# AT91SAM9M11 register map
Vendor: Atmel; File version: 20130207
CPU: 
Registers are 32-bit, read-write, no defined reset value unless marked. A register's access mark holds for its fields unless they carry their own. Offsets are from the block's base; [hi:lo] are bit positions; {n}, {i} and the like mark numbered series; 'fields as' and 'values as' point back to an identical list.

## PMC — Power Management Controller
Base 0xFFFFFC00
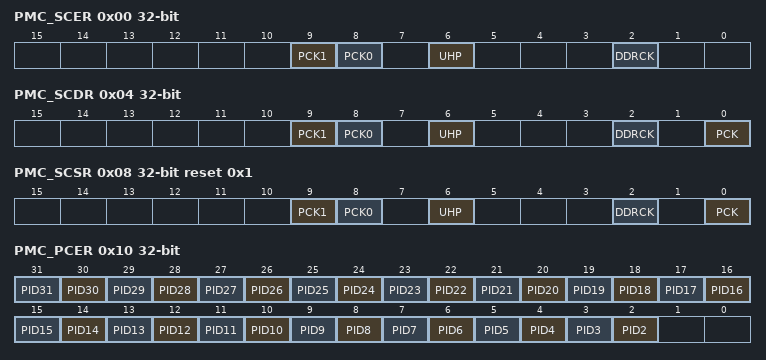
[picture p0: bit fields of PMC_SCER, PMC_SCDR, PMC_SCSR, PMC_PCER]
0x00 PMC_SCER wo — System Clock Enable Register
  [9] PCK1 — Programmable Clock 1 Output Enable
  [8] PCK0 — Programmable Clock 0 Output Enable
  [6] UHP — USB Host OHCI Clocks Enable
  [2] DDRCK — DDR Clock Enable
0x04 PMC_SCDR wo — System Clock Disable Register
  [9] PCK1 — Programmable Clock 1 Output Disable
  [8] PCK0 — Programmable Clock 0 Output Disable
  [6] UHP — USB Host OHCI Clock Disable
  [2] DDRCK — DDR Clock Disable
  [0] PCK — Processor Clock Disable
0x08 PMC_SCSR ro reset 0x1 — System Clock Status Register
  [9] PCK1 — Programmable Clock 1 Output Status
  [8] PCK0 — Programmable Clock 0 Output Status
  [6] UHP — USB Host Port Clock Status
  [2] DDRCK — DDR Clock Status
  [0] PCK — Processor Clock Status
0x10 PMC_PCER wo — Peripheral Clock Enable Register
  [n] PID{n} (n=2..31) — Peripheral Clock {n} Enable
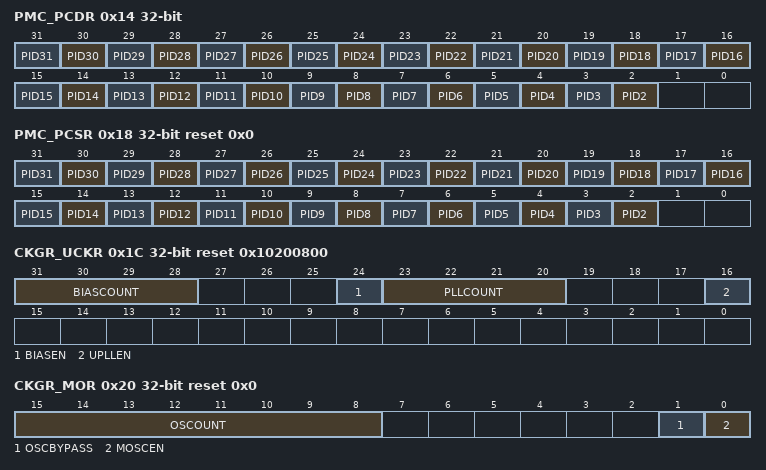
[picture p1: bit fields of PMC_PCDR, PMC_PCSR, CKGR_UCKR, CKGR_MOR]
0x14 PMC_PCDR wo — Peripheral Clock Disable Register
  [n] PID{n} (n=2..31) — Peripheral Clock {n} Disable
0x18 PMC_PCSR ro reset 0x0 — Peripheral Clock Status Register
  [n] PID{n} (n=2..31) — Peripheral Clock {n} Status
0x1C CKGR_UCKR reset 0x10200800 — UTMI Clock Register
  [31:28] BIASCOUNT — UTMI BIAS Start-up Time
  [24] BIASEN — UTMI BIAS Enable
  [23:20] PLLCOUNT — UTMI PLL Start-up Time
  [16] UPLLEN — UTMI PLL Enable
0x20 CKGR_MOR reset 0x0 — Main Oscillator Register
  [15:8] OSCOUNT — Main Oscillator Start-up Time
  [1] OSCBYPASS — Oscillator Bypass
  [0] MOSCEN — Main Oscillator Enable
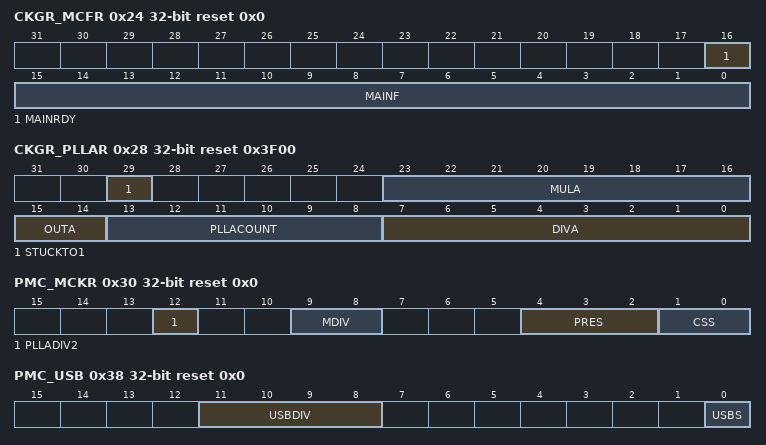
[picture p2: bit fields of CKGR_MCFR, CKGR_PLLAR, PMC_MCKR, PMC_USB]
0x24 CKGR_MCFR ro reset 0x0 — Main Clock Frequency Register
  [16] MAINRDY — Main Clock Ready
  [15:0] MAINF — Main Clock Frequency
0x28 CKGR_PLLAR reset 0x3F00 — PLLA Register
  [29] STUCKTO1
  [23:16] MULA — PLLA Multiplier
  [15:14] OUTA — PLLA Clock Frequency Range
  [13:8] PLLACOUNT — PLLA Counter
  [7:0] DIVA — Divider A
0x30 PMC_MCKR reset 0x0 — Master Clock Register
  [12] PLLADIV2 — PLLA divisor by 2
  [9:8] MDIV — Master Clock Division
  [4:2] PRES — Master/Processor Clock Prescaler
  [1:0] CSS — Master/Processor Clock Source Selection
0x38 PMC_USB reset 0x0 — USB Clock Register
  [11:8] USBDIV — Divider for USB OHCI Clock.
  [0] USBS — USB OHCI Input clock selection
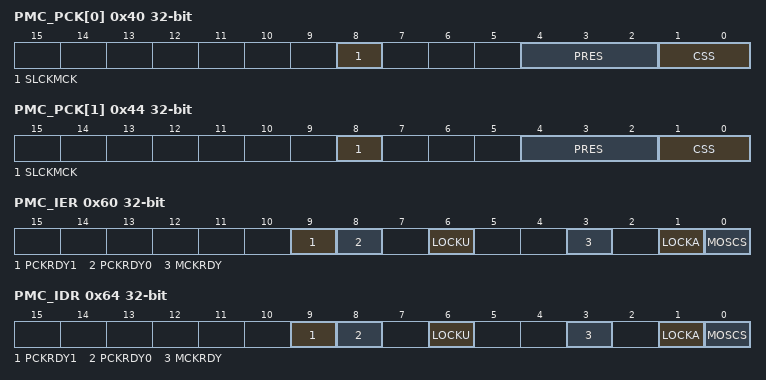
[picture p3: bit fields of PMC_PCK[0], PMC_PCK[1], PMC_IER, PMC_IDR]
0x40 PMC_PCK[0] — Programmable Clock 0 Register
  [8] SLCKMCK — Slow Clock or Master Clock Selection
  [4:2] PRES — Programmable Clock Prescaler
  [1:0] CSS — Master Clock Selection
0x44 PMC_PCK[1] — Programmable Clock 0 Register
  fields as PMC_PCK[0]
0x60 PMC_IER wo — Interrupt Enable Register
  [9] PCKRDY1 — Programmable Clock Ready 1 Interrupt Enable
  [8] PCKRDY0 — Programmable Clock Ready 0 Interrupt Enable
  [6] LOCKU — UTMI PLL Lock Interrupt Enable
  [3] MCKRDY — Master Clock Ready Interrupt Enable
  [1] LOCKA — PLL Lock Interrupt Enable
  [0] MOSCS — Main Oscillator Status Interrupt Enable
0x64 PMC_IDR wo — Interrupt Disable Register
  [9] PCKRDY1 — Programmable Clock Ready 1 Interrupt Disable
  [8] PCKRDY0 — Programmable Clock Ready 0 Interrupt Disable
  [6] LOCKU — UTMI PLL Lock Interrupt Disable
  [3] MCKRDY — Master Clock Ready Interrupt Disable
  [1] LOCKA — PLLA Lock Interrupt Disable
  [0] MOSCS — Main Oscillator Status Interrupt Disable
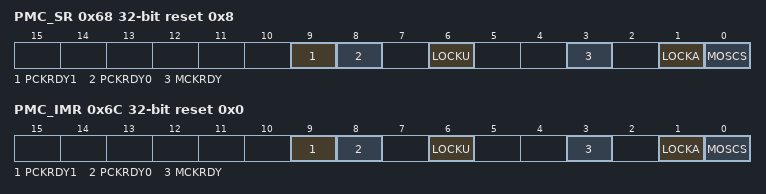
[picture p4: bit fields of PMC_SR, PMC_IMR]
0x68 PMC_SR ro reset 0x8 — Status Register
  [9] PCKRDY1 — Programmable Clock Ready Status
  [8] PCKRDY0 — Programmable Clock Ready Status
  [6] LOCKU — UPLL Lock Status
  [3] MCKRDY — Master Clock Status
  [1] LOCKA — PLLA Lock Status
  [0] MOSCS — MOSCS Flag Status
0x6C PMC_IMR ro reset 0x0 — Interrupt Mask Register
  [9] PCKRDY1 — Programmable Clock Ready 1 Interrupt Mask
  [8] PCKRDY0 — Programmable Clock Ready 0 Interrupt Mask
  [6] LOCKU — UTMI PLL Lock Interrupt Mask
  [3] MCKRDY — Master Clock Ready Interrupt Mask
  [1] LOCKA — PLLA Lock Interrupt Mask
  [0] MOSCS — Main Oscillator Status Interrupt Mask
